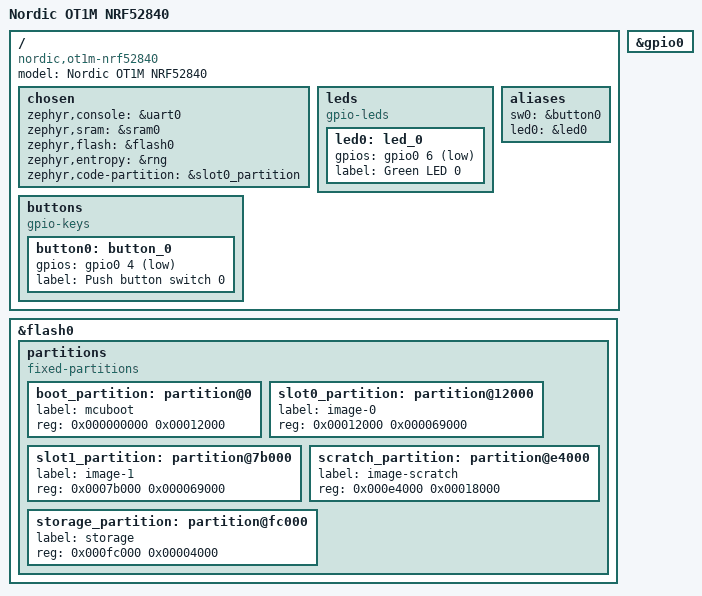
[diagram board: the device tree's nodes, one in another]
/*
 *
 * SPDX-License-Identifier: Apache-2.0
 */

/dts-v1/;
#include <nordic/nrf52840_qiaa.dtsi>

/ {
	model = "Nordic OT1M NRF52840";
	compatible = "nordic,ot1m-nrf52840";

	chosen {
		zephyr,console = &uart0;
		zephyr,sram = &sram0;
		zephyr,flash = &flash0;
		zephyr,entropy = &rng;
		zephyr,code-partition = &slot0_partition;
	};

    leds {
		compatible = "gpio-leds";
		led0: led_0 {
			gpios = <&gpio0 6 GPIO_ACTIVE_LOW>;
			label = "Green LED 0";
		};
	};

	buttons {
		compatible = "gpio-keys";
		button0: button_0 {
			gpios = <&gpio0 4 (GPIO_PULL_UP | GPIO_ACTIVE_LOW)>;
			label = "Push button switch 0";
		};
	};

    aliases {
		sw0 = &button0;
		led0 = &led0;
    };
};

&gpio0 {
	status = "okay";
};


&flash0 {
	partitions {
		compatible = "fixed-partitions";
		#address-cells = <1>;
		#size-cells = <1>;

		/* The size of this partition ensures that MCUBoot can be built
		 * with an RTT console, CDC ACM support, and w/o optimizations.
		 */
		boot_partition: partition@0 {
			label = "mcuboot";
			reg = <0x000000000 0x00012000>;
		};

		slot0_partition: partition@12000 {
			label = "image-0";
			reg = <0x00012000 0x000069000>;
		};
		slot1_partition: partition@7b000 {
			label = "image-1";
			reg = <0x0007b000 0x000069000>;
		};
		scratch_partition: partition@e4000 {
			label = "image-scratch";
			reg = <0x000e4000 0x00018000>;
		};
		storage_partition: partition@fc000 {
			label = "storage";
			reg = <0x000fc000 0x00004000>;
		};
	};
};

